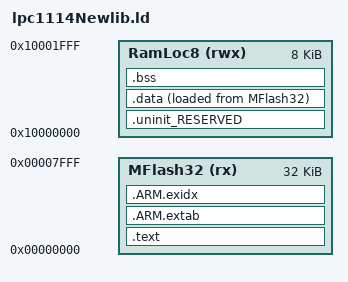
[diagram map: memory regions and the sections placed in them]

GROUP(libgcc.a libc.a libm.a)

MEMORY
{
  /* Define each memory region */
  MFlash32 (rx) : ORIGIN = 0x0, LENGTH = 0x8000 /* 32k */
  RamLoc8 (rwx) : ORIGIN = 0x10000000, LENGTH = 0x2000 /* 8k */

}
  /* Define a symbol for the top of each memory region */
  __top_MFlash32 = 0x0 + 0x8000;
  __top_RamLoc8 = 0x10000000 + 0x2000;

ENTRY(ResetISR)

SECTIONS
{

	/* MAIN TEXT SECTION */	
	.text : ALIGN(4)
	{
		FILL(0xff)
		KEEP(*(.isr_vector))
		
		/* Global Section Table */
		. = ALIGN(4) ;
		__section_table_start = .;
		__data_section_table = .;
		LONG(LOADADDR(.data));
		LONG(    ADDR(.data)) ;
		LONG(  SIZEOF(.data));
		__data_section_table_end = .;
		__bss_section_table = .;
		LONG(    ADDR(.bss));
		LONG(  SIZEOF(.bss));
		__bss_section_table_end = .;
		__section_table_end = . ;
		/* End of Global Section Table */
		

		*(.after_vectors*)
		
		/* Code Read Protect data */
		. = 0x000002FC ;
		PROVIDE(__CRP_WORD_START__ = .) ;
		KEEP(*(.crp))
		PROVIDE(__CRP_WORD_END__ = .) ;
		ASSERT(!(__CRP_WORD_START__ == __CRP_WORD_END__), "Linker CRP Enabled, but no CRP_WORD provided within application");
		/* End of Code Read Protect */
		
		*(.text*)
		*(.rodata .rodata.*)
		. = ALIGN(4);
		
	} > MFlash32

	/*
	 * for exception handling/unwind - some Newlib functions (in common
	 * with C++ and STDC++) use this.
	 */
	.ARM.extab : ALIGN(4)
	{
		*(.ARM.extab* .gnu.linkonce.armextab.*)
	} > MFlash32
	__exidx_start = .;
	
	.ARM.exidx : ALIGN(4)
	{
		*(.ARM.exidx* .gnu.linkonce.armexidx.*)
	} > MFlash32
	__exidx_end = .;
	
	_etext = .;
		
	
	/* MAIN DATA SECTION */

	.uninit_RESERVED : ALIGN(4)
	{
		KEEP(*(.bss.$RESERVED*))
	} > RamLoc8

	.data : ALIGN(4)
	{
		FILL(0xff)
		_data = .;
		*(vtable)
		*(.data*)
		. = ALIGN(4) ;
		_edata = .;
	} > RamLoc8 AT>MFlash32


	/* MAIN BSS SECTION */
	.bss : ALIGN(4)
	{
		_bss = .;
		*(.bss*)
		*(COMMON)
		. = ALIGN(4) ;
		_ebss = .;
		PROVIDE(end = .);
	} > RamLoc8
	
	PROVIDE(_pvHeapStart = .);
	PROVIDE(_vStackTop = __top_RamLoc8 - 0);
}

